# STM32L151xDx register map
File version: 1.0
Registers are 32-bit, read-write, reset 0x0 unless marked. A register's access mark holds for its fields unless they carry their own. Offsets are from the block's base; [hi:lo] are bit positions; lines under a group give offsets from that group; {n}, {i} and the like mark numbered series.

## ADC1 — Analog to Digital Converter
Base 0x40012400
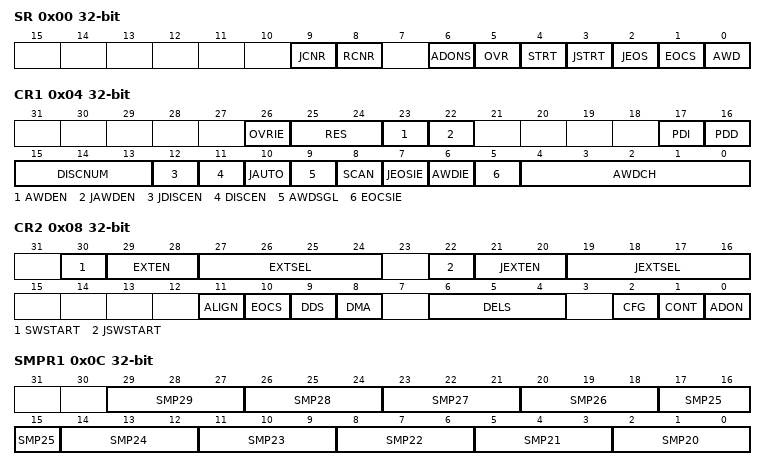
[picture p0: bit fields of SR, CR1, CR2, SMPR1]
0x00 SR — ADC status register
  [9] JCNR — ADC group injected not ready flag
  [8] RCNR — ADC group regular not ready flag
  [6] ADONS — ADC ready flag
  [5] OVR — ADC group regular overrun flag
  [4] STRT — ADC group regular conversion start flag
  [3] JSTRT — ADC group injected conversion start flag
  [2] JEOS — ADC group injected end of sequence conversions flag
  [1] EOCS — ADC group regular end of unitary conversion or end of sequence conversions flag
  [0] AWD — ADC analog watchdog 1 flag
0x04 CR1 — ADC control register 1
  [26] OVRIE — ADC group regular overrun interrupt
  [25:24] RES — ADC resolution
    0=RESOLUTION_12B (ADC resolution 12 bits); 1=RESOLUTION_10B (ADC resolution 10 bits); 2=RESOLUTION_8B (ADC resolution 8 bits); 3=RESOLUTION_6B (ADC resolution 6 bits)
  [23] AWDEN — ADC analog watchdog 1 enable on scope ADC group regular
  [22] JAWDEN — ADC analog watchdog 1 enable on scope ADC group injected
  [17] PDI — ADC power down during idle phase
  [16] PDD — ADC power down during auto delay phase
  [15:13] DISCNUM — ADC group regular sequencer discontinuous number of ranks
  [12] JDISCEN — ADC group injected sequencer discontinuous mode
    0=DISABLE (ADC group injected sequencer discontinuous mode disable); 1=DISCONT_1RANK (ADC group injected sequencer discontinuous mode enable with sequence interruption every rank)
  [11] DISCEN — ADC group regular sequencer discontinuous mode
  [10] JAUTO — ADC group injected automatic trigger mode
    0=INDEPENDENT (ADC group injected conversion trigger independent. Setting mandatory if ADC group injected injected trigger source is set to an external trigger.); 1=FROM_GRP_REGULAR (ADC group injected conversion trigger from ADC group regular. Setting compliant only with group injected trigger source set to SW start, without any further action on ADC group injected conversion start or stop: in this case, ADC group injected is controlled only from ADC group regular.)
  [9] AWDSGL — ADC analog watchdog 1 monitoring a single channel or all channels
  [8] SCAN — ADC scan mode
    0=DISABLE (ADC conversion is performed in unitary conversion mode (one channel converted, that defined in rank 1). Configuration of both groups regular and injected sequencers (sequence length, ...) is discarded: equivalent to length of 1 rank.); 1=ENABLE (ADC conversions are performed in sequence conversions mode, according to configuration of both groups regular and injected sequencers (sequence length, ...).)
  [7] JEOSIE — ADC group injected end of sequence conversions interrupt
  [6] AWDIE — ADC analog watchdog 1 interrupt
  [5] EOCSIE — ADC group regular end of unitary conversion or end of sequence conversions interrupt
  [4:0] AWDCH — ADC analog watchdog 1 monitored channel selection
0x08 CR2 — ADC control register 2
  [30] SWSTART — ADC group regular conversion start
  [29:28] EXTEN — ADC group regular external trigger polarity
    1=RISING (ADC group regular conversion trigger polarity set to rising edge); 2=FALLING (ADC group regular conversion trigger polarity set to falling edge); 3=RISINGFALLING (ADC group regular conversion trigger polarity set to both rising and falling edges)
  [27:24] EXTSEL — ADC group regular external trigger source
  [22] JSWSTART — ADC group injected conversion start
  [21:20] JEXTEN — ADC group injected external trigger polarity
    1=RISING (ADC group injected conversion trigger polarity set to rising edge); 2=FALLING (ADC group injected conversion trigger polarity set to falling edge); 3=RISINGFALLING (ADC group injected conversion trigger polarity set to both rising and falling edges)
  [19:16] JEXTSEL — ADC group injected external trigger source
  [11] ALIGN — ADC data alignment
    0=RIGHT (ADC conversion data alignment: right aligned (alignment on data register LSB bit 0)); 1=LEFT (ADC conversion data alignment: left aligned (alignment on data register MSB bit 15))
  [10] EOCS — ADC end of unitary or end of sequence conversions selection
    0=SEQUENCE_CONV (ADC flag EOC (end of unitary conversion) selected); 1=UNITARY_CONV (ADC flag EOS (end of sequence conversions) selected)
  [9] DDS — ADC DMA transfer configuration
  [8] DMA — ADC DMA transfer enable
  [6:4] DELS — ADC auto delay selection
    0=NONE (ADC low power mode auto wait not activated); 1=AUTOWAIT (ADC low power mode auto wait: Dynamic low power mode, ADC conversions are performed only when necessary (when previous ADC conversion data is read). See description with function @ref LL_ADC_SetLowPowerModeAutoWait().); 2=AUTOWAIT_7_APBCLOCKCYCLES (ADC low power mode auto wait: Insert a delay between ADC conversions: 7 APB clock cycles); 3=AUTOWAIT_15_APBCLOCKCYCLES (ADC low power mode auto wait: Insert a delay between ADC conversions: 15 APB clock cycles); 4=AUTOWAIT_31_APBCLOCKCYCLES (ADC low power mode auto wait: Insert a delay between ADC conversions: 31 APB clock cycles); 5=AUTOWAIT_63_APBCLOCKCYCLES (ADC low power mode auto wait: Insert a delay between ADC conversions: 63 APB clock cycles); 6=AUTOWAIT_127_APBCLOCKCYCLES (ADC low power mode auto wait: Insert a delay between ADC conversions: 127 APB clock cycles); 7=AUTOWAIT_255_APBCLOCKCYCLES (ADC low power mode auto wait: Insert a delay between ADC conversions: 255 APB clock cycles)
  [2] CFG — ADC channels bank selection
    0=A (ADC channels bank A); 1=B (ADC channels bank B, available in devices categories 3, 4, 5.)
  [1] CONT — ADC group regular continuous conversion mode
    0=SINGLE (ADC conversions are performed in single mode: one conversion per trigger); 1=CONTINUOUS (ADC conversions are performed in continuous mode: after the first trigger, following conversions launched successively automatically)
  [0] ADON — ADC enable
0x0C SMPR1 — ADC sample time register 1
  [3n-58:3n-60] SMP{n} (n=20..29) — ADC channel {n} sampling time selection
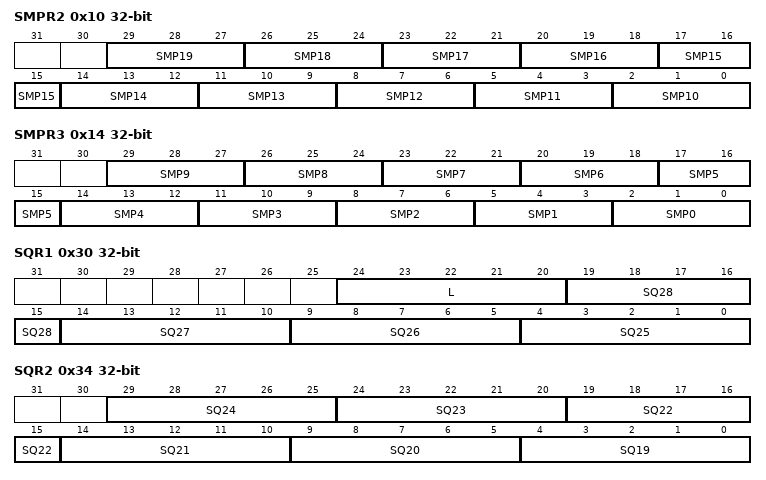
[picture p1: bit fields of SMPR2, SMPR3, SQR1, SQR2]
0x10 SMPR2 — ADC sample time register 2
  [3n-28:3n-30] SMP{n} (n=16..19) — ADC channel {n} sampling time selection
  [17:15] SMP15 — ADC channel 5 sampling time selection
  [3n-28:3n-30] SMP{n} (n=10..14) — ADC channel {n} sampling time selection
0x14 SMPR3 — ADC sample time register 3
  [3n+2:3n] SMP{n} (n=0..9) — ADC channel {n} sampling time selection
{0x14+4i} JOFR{i} (i=1..4) — ADC injected channel data
  [11:0] JOFFSET{i} — ADC group injected sequencer rank {i} offset value
0x28 HTR — ADC watchdog higher threshold register
  [11:0] HT — ADC analog watchdog 1 threshold high
0x2C LTR — ADC watchdog lower threshold register
  [11:0] LT — ADC analog watchdog 1 threshold low
0x30 SQR1 — ADC regular sequence register 1
  [24:20] L — ADC group regular sequencer scan length
    0=DISABLE (ADC group regular sequencer disable (equivalent to sequencer of 1 rank: ADC conversion on only 1 channel)); {v}=ENABLE_{v+1}RANKS (ADC group regular sequencer enable with {v+1} ranks in the sequence) (v=1..16); {v}=ENABLE_{v+1}RANKS (ADC group regular sequencer enable with {v+1} ranks in the sequence) (v=18..27)
  [5n-121:5n-125] SQ{n} (n=25..28) — ADC group regular sequencer rank {n}
0x34 SQR2 — ADC regular sequence register 2
  [5n-91:5n-95] SQ{n} (n=19..24) — ADC group regular sequencer rank {n}
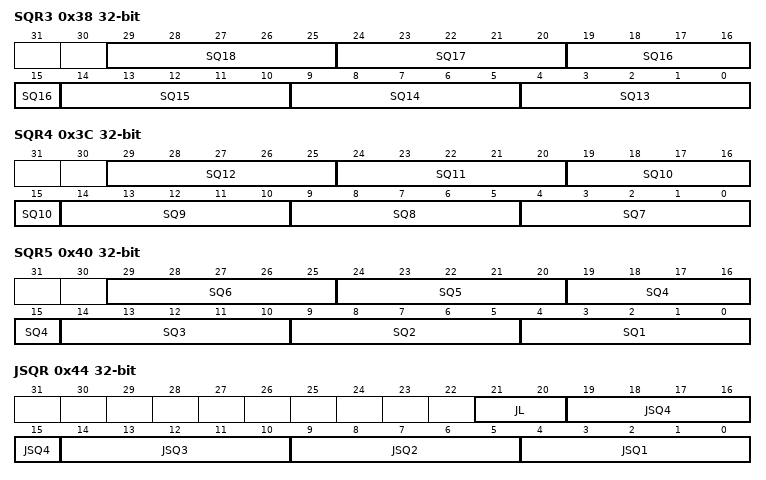
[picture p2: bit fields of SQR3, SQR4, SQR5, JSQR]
0x38 SQR3 — ADC regular sequence register 3
  [5n-61:5n-65] SQ{n} (n=13..18) — ADC group regular sequencer rank {n}
0x3C SQR4 — ADC regular sequence register 4
  [5n-31:5n-35] SQ{n} (n=7..12) — ADC group regular sequencer rank {n}
0x40 SQR5 — ADC regular sequence register 5
  [5n-1:5n-5] SQ{n} (n=1..6) — ADC group regular sequencer rank {n}
0x44 JSQR — ADC injected sequence register
  [21:20] JL — ADC group injected sequencer scan length
    0=DISABLE (ADC group injected sequencer disable (equivalent to sequencer of 1 rank: ADC conversion on only 1 channel)); 1=ENABLE_2RANKS (ADC group injected sequencer enable with 2 ranks in the sequence); 2=ENABLE_3RANKS (ADC group injected sequencer enable with 3 ranks in the sequence); 3=ENABLE_4RANKS (ADC group injected sequencer enable with 4 ranks in the sequence)
  [5n-1:5n-5] JSQ{n} (n=1..4) — ADC group injected sequencer rank {n}
{0x44+4i} JDR{i} (i=1..4) — ADC injected data register {i}
  [15:0] JDATA — ADC group injected sequencer rank {i} conversion data
0x58 DR — ADC regular data register
  [15:0] DATA — ADC group regular conversion data
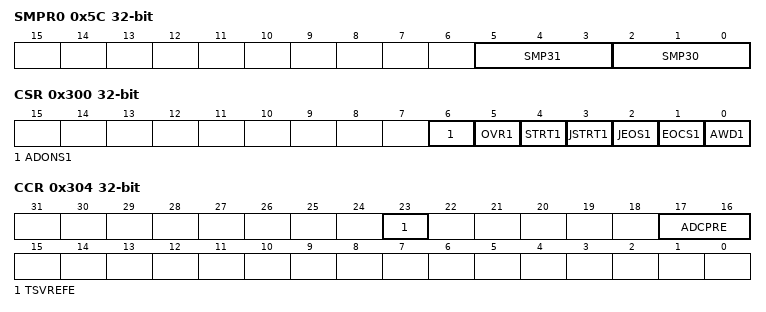
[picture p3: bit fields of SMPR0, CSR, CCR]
0x5C SMPR0 — ADC sample time register 0
  [5:3] SMP31 — ADC channel 31 sampling time selection
  [2:0] SMP30 — ADC channel 30 sampling time selection
0x300 CSR — ADC common status register
  [6] ADONS1 — ADC multimode master ready flag
  [5] OVR1 — ADC multimode master group regular overrun flag
  [4] STRT1 — ADC multimode master group regular conversion start flag
  [3] JSTRT1 — ADC multimode master group injected conversion start flag
  [2] JEOS1 — ADC multimode master group injected end of sequence conversions flag
  [1] EOCS1 — ADC multimode master group regular end of unitary conversion or end of sequence conversions flag
  [0] AWD1 — ADC multimode master analog watchdog 1 flag
0x304 CCR — ADC common control register
  [23] TSVREFE — ADC internal path to VrefInt and temperature sensor enable
    0=NONE (ADC measurement paths all disabled); 1=VREFINT (ADC measurement path to internal channel VrefInt)
  [17:16] ADCPRE — ADC clock source asynchronous prescaler
    0=DIV1 (ADC asynchronous clock without prescaler); 1=DIV2 (ADC asynchronous clock with prescaler division by 2); 2=DIV4 (ADC asynchronous clock with prescaler division by 4)
